# Musca register map
Vendor: ARM Ltd.; Series: ARMv8-M Mainline; File version: 1.0
CPU: CM33 r0p1, little endian, MPU, no FPU, 3 interrupt priority bits, 8 SAU regions
Registers are 32-bit, read-write, reset 0x0 unless marked. A register's access mark holds for its fields unless they carry their own. Offsets are from the block's base; [hi:lo] are bit positions.

## SCC — Serial Communication Controller
Base 0x4010C000
Same registers: SCC_Secure 0x5010C000
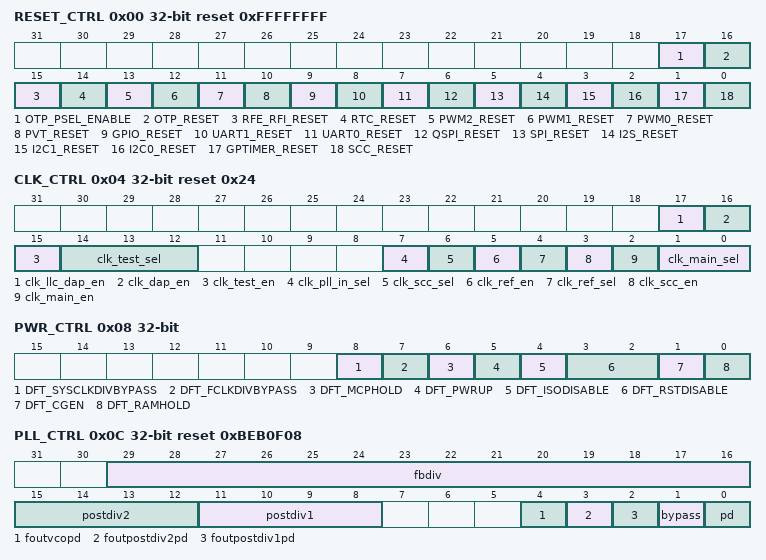
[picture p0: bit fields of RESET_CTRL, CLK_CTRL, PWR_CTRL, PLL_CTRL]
0x00 RESET_CTRL reset 0xFFFFFFFF
  [17] OTP_PSEL_ENABLE — PSEL enable
  [16] OTP_RESET — Reset Active low
  [15] RFE_RFI_RESET — Reset Active low
  [14] RTC_RESET — Reset Active low
  [13] PWM2_RESET — Reset Active low
  [12] PWM1_RESET — Reset Active low
  [11] PWM0_RESET — Reset Active low
  [10] PVT_RESET — Reset Active low
  [9] GPIO_RESET — Reset Active low
  [8] UART1_RESET — Reset Active low
  [7] UART0_RESET — Reset Active low
  [6] QSPI_RESET — Reset Active low
  [5] SPI_RESET — Reset Active low
  [4] I2S_RESET — Reset Active low
  [3] I2C1_RESET — Reset Active low
  [2] I2C0_RESET — Reset Active low
  [1] GPTIMER_RESET — Reset Active low
  [0] SCC_RESET — Reset Active low
0x04 CLK_CTRL reset 0x24
  [17] clk_llc_dap_en — LLC DAP clock enable
  [16] clk_dap_en — DAP clock enable
  [15] clk_test_en — Test clock enable
  [14:12] clk_test_sel — Reset Active low
    0=PLLVCOCLK; 1=FCLK; 2=SYSCLK; 3=RM_CLK32K; 4=RM_CLK32M; 5=SCCCLK
  [7] clk_pll_in_sel — 0: Pad 32K REFCLK; 1: Reserved
  [6] clk_scc_sel — 0: SCCCLK; 1: FASTCLK
  [5] clk_ref_en — Clock ref enable
  [4] clk_ref_sel — 0: REFCLK; 1: FASTCLK
  [3] clk_scc_en — Clock scc enable
  [2] clk_main_en — Clock main enable
  [1:0] clk_main_sel — clk_main_selw
0x08 PWR_CTRL
  [8] DFT_SYSCLKDIVBYPASS, [7] DFT_FCLKDIVBYPASS, [6] DFT_MCPHOLD, [5] DFT_PWRUP, [4] DFT_ISODISABLE, [3:2] DFT_RSTDISABLE, [1] DFT_CGEN, [0] DFT_RAMHOLD
0x0C PLL_CTRL reset 0xBEB0F08
  [29:16] fbdiv — PLL Feedback divide value
  [15:12] postdiv2 — Second post divide value (for FOUT2). Not used
  [11:8] postdiv1 — irst post divide value (for FOUT1)
  [4] foutvcopd — VCO rate output clock power down. Not used
  [3] foutpostdiv2pd — Second post divide power down. Not used
  [2] foutpostdiv1pd — First post divide power down. (0: ON, 1: OFF)
  [1] bypass — FREF is bypassed to FOUT1 and FOUT2
  [0] pd — Power down for PLL (0: PLL ON, 1: PLL OFF)
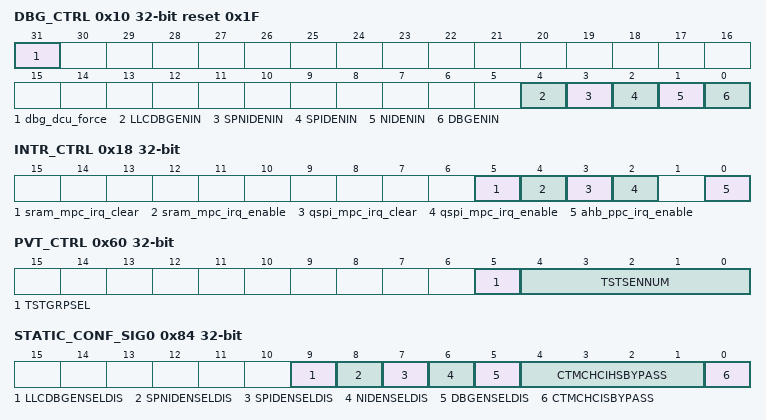
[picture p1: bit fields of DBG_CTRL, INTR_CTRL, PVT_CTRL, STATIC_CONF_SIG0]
0x10 DBG_CTRL reset 0x1F
  [31] dbg_dcu_force — 0: use Crypto DCU; 1: Use SCC signal
  [4] LLCDBGENIN
  [3] SPNIDENIN
  [2] SPIDENIN
  [1] NIDENIN
  [0] DBGENIN
0x14 SRAM_CTRL — Power gate enable of SRAM blocks
0x18 INTR_CTRL
  [5] sram_mpc_irq_clear, [4] sram_mpc_irq_enable, [3] qspi_mpc_irq_clear, [2] qspi_mpc_irq_enable, [0] ahb_ppc_irq_enable
0x20 CPU0_VTOR_SRAM — Reset vector for CPU0 Secure Mode
0x24 CPU0_VTOR_FLASH
0x28 CPU1_VTOR_SRAM — Reset vector for CPU1 Secure Mode
0x2C CPU1_VTOR_FLASH
0x30 IOMUX_MAIN_INSEL reset 0xFFFFFFFF — IO Main Function Input Data Select
  [31:0] main_func_idata_sel — 1: Main function of corresponding IO Selected
0x34 IOMUX_MAIN_OUTSEL reset 0xFFFFFFFF — IO Main Function Output Data Select
  [31:0] main_func_odata_sel — 1: Main function of corresponding IO Selected
0x38 IOMUX_MAIN_OENSEL reset 0xFFFFFFFF — IO Main Function Output Enable Select
  [31:0] main_func_outen_sel — 1: Main function OEN Selected
0x3C IOMUX_MAIN_DEFAULT_IN — Default In value to main function IPs when main function is not selected
0x40 IOMUX_ALTF1_INSEL reset 0xFFFFFFFF — IO Alt Function1 Input Data Select
  [31:0] alt_func1_idata_sel — 1: Alt function1 of corresponding IO Selected
0x44 IOMUX_ALTF1_OUTSEL reset 0xFFFFFFFF — IO Alt Function1 Output Data Select
  [31:0] alt_func1_odata_sel — 1: Alt function1 of corresponding IO Selected
0x48 IOMUX_ALTF1_OENSEL reset 0xFFFFFFFF — IO Alt Function1 Output Enable Select
  [31:0] alt_func1_outen_sel — 1: Alt function1 OEN Selected
0x4C IOMUX_ALTF1_DEFAULT_IN — Default In value to Alt Function1 IPs when Alt Function1 is not selected
0x50 IOMUX_ALTF2_INSEL reset 0xFFFFFFFF — IO Alt Function2 Input Data Select
  [31:0] alt_func2_idata_sel — 1: Alt function2 of corresponding IO Selected
0x54 IOMUX_ALTF2_OUTSEL reset 0xFFFFFFFF — IO Alt Function2 Output Data Select
  [31:0] alt_func2_odata_sel — 1: Alt function2 of corresponding IO Selected
0x58 IOMUX_ALTF2_OENSEL reset 0xFFFFFFFF — IO Alt Function2 Output Enable Select
  [31:0] alt_func2_outen_sel — 1: Alt function2 OEN Selected
0x5C IOMUX_ALTF2_DEFAULT_IN — Default In value to Alt Function2 IPs when Alt Function2 is not selected
0x60 PVT_CTRL — PVT control register
  [5] TSTGRPSEL, [4:0] TSTSENNUM
0x64 SPARE0 — Reserved
0x68 IOPAD_DS0 reset 0xFFFFFFFF — Drive Select0.
0x6C IOPAD_DS1 reset 0xFFFFFFFF — Drive Select1.
0x70 IOPAD_PE reset 0xFFFFFFFF — Pull Enable; 0: disabled, 1: enabled
0x74 IOPAD_PS reset 0xFFFFFFFF — Pull mode select; 0: pull down, 1: pull up
0x78 IOPAD_SR reset 0xFFFFFFFF — Selw rate; 0: slow, 1: fast
0x7C IOPAD_IS reset 0xFFFFFFFF — Input mode select; 0: cmos, 1: shmitt trigger
0x80 SRAM_RW_MARGINE — Reserved
0x84 STATIC_CONF_SIG0 — PVT control register
  [9] LLCDBGENSELDIS
  [8] SPNIDENSELDIS
  [7] SPIDENSELDIS
  [6] NIDENSELDIS
  [5] DBGENSELDIS
  [4:1] CTMCHCIHSBYPASS — 0: Asynchronous, 1: Synchronous
  [0] CTMCHCISBYPASS — 0: Asynchronous, 1: Synchronous
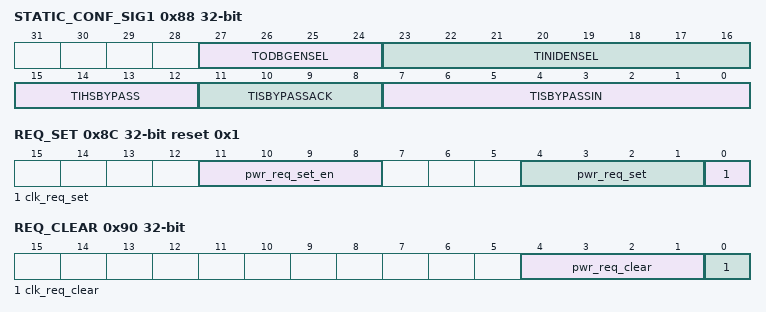
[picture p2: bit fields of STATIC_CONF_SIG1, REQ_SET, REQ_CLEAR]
0x88 STATIC_CONF_SIG1 — PVT control register
  [27:24] TODBGENSEL, [23:16] TINIDENSEL, [15:12] TIHSBYPASS, [11:8] TISBYPASSACK, [7:0] TISBYPASSIN
0x8C REQ_SET reset 0x1
  [11:8] pwr_req_set_en, [4:1] pwr_req_set, [0] clk_req_set
0x90 REQ_CLEAR
  [4:1] pwr_req_clear, [0] clk_req_clear
0x94 IOMUX_ALTF3_INSEL reset 0xFFFFFFFF — IO Alt Function3 Input Data Select
  [31:0] alt_func3_idata_sel — 1: Alt function3 of corresponding IO Selected
0x98 IOMUX_ALTF3_OUTSEL reset 0xFFFFFFFF — IO Alt Function3 Output Data Select
  [31:0] alt_func3_odata_sel — 1: Alt function3 of corresponding IO Selected
0x9C IOMUX_ALTF3_OENSEL reset 0xFFFFFFFF — IO Alt Function3 Output Enable Select
  [31:0] alt_func3_outen_sel — 1: Alt function3 OEN Selected
0xA0 IOMUX_ALTF3_DEFAULT_IN — Default In value to Alt Function3 IPs when Alt Function3 is not selected
0xA4 PCSM_CTRL_OVEERIDE — Q-Channels QACTIVE Override
0xA8 PD_CPU0_ISO_OVEERIDE — CPU0 Isolation Override
0xAC PD_CPU1_ISO_OVEERIDE — CPU1 Isolation Override
0xB0 SYS_SRAM_RW_ASSIST0 reset 0x2400240 — CPU 0 icache sram ldata assist
0xB4 SYS_SRAM_RW_ASSIST1 reset 0x2400240 — CPU 0 icache sramtag assist
0xB8 SYS_SRAM_RW_ASSIST2 reset 0x2400240 — CPU 1 icache ldata assist
0xBC SYS_SRAM_RW_ASSIST3 reset 0x2400240 — CPU 1 icache sramtag assist
0xC0 SYS_SRAM_RW_ASSIST4 reset 0x2400240 — System sram assist
0xC4 SYS_SRAM_RW_ASSIST5 reset 0x4400440 — System sram assist
0xD4 CRYPTO_SRAM_RW_ASSIST0 reset 0x2400240 — Crypto ram pka
0xD8 CRYPTO_SRAM_RW_ASSIST1 reset 0x2400240 — Crypto sec sram
0xDC CRYPTO_SRAM_RW_ASSIST2 — Reserved
0xE0 REQ_EDGE_SEL — Power clock request edge select
0xE4 REQ_ENABLE — Power clock request enable
